# ESP32S3_RADIO register map
File version: 0.1.0
Registers are 32-bit, read-write, no defined reset value unless marked. A register's access mark holds for its fields unless they carry their own. Offsets are from the block's base; [hi:lo] are bit positions; {n}, {i} and the like mark numbered series.

## DUMP — Dump and DAC engine The Wi-Fi MAC's debug dump engine moves raw baseband words between the radio and one 64 KiB SRAM bank (see "SRAM bank ownership"). Its page, 0x60033000, has no name in the HAL. Layout from upstream esp-sdr; the DAC side from librftest's `dactrig()`. **Wi-Fi MAC interrupt.** CPU interrupt line 0 (`ETS_WMAC_INUM`, `modules/hal/espressif/components/soc/esp32s3/include/soc/soc.h:212`); `esp_sdr_ring_run()` disables it on its CPU (hardware-quirks.md, "Capture and DAC engine"; `lib/esp_sdr/src/esp_sdr_ring.c:508-538`).
Base 0x60033000
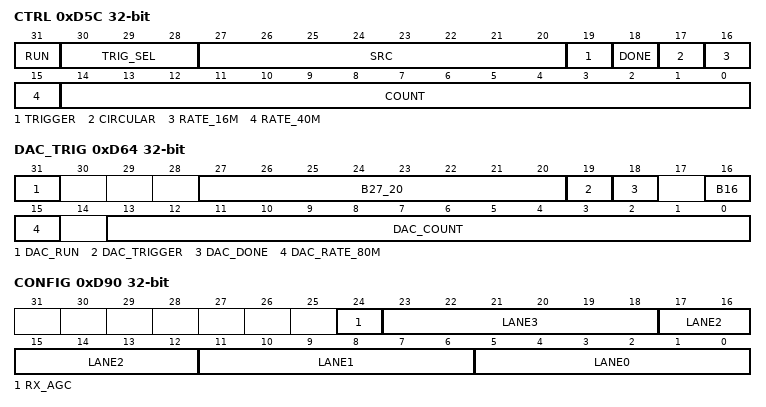
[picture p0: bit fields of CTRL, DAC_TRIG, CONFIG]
0xD5C CTRL — Receive side: run, trigger and count of a capture With neither DUMP_RATE_16M nor DUMP_RATE_40M the engine captures at 80 MS/s (4096 samples in 51 to 60 us). One-shot sequence: DUMP_CTRL_REG = 0, DUMP_CONFIG_REG, bank select, `DUMP_RUN | rate | count`, the same with DUMP_TRIGGER, the same without, poll DUMP_DONE, DUMP_CTRL_REG = 0, restore the bank select. The engine can stop early without any error flag (hardware-quirks.md, "Capture and DAC engine"). Evidence: `lib/esp_sdr/src/esp_sdr_rx.c:246-326` (sequence), `lib/esp_sdr/src/esp_sdr_rx.c:287-293, 321-323` (early stop)
  [31] RUN — Enables the engine. Evidence: *working* `lib/esp_sdr/src/esp_sdr_rx.c:300-310`
  [30:28] TRIG_SEL — The vendor `adctrig()`'s second argument: 0 = software trigger (DUMP_TRIGGER); 5 and 6 make it send frames while it waits. Seen 0. The trigger select could take work off the CPU; lead, not tried. Evidence: *decompile* S3 `mac_common.o` Evidence: *decompile* S3 `libphy.a` (lead)
  [27:20] SRC — The vendor's third argument; upstream calls it the source. Seen 0. Evidence: *decompile* S3 `mac_common.o`; *upstream* `modules/lib/esp-sdr/main/targets/esp32s3/receiver.c:164`
  [19] TRIGGER wo — Write 1, then 0, to start a one-shot capture. Evidence: *working* `lib/esp_sdr/src/esp_sdr_rx.c:308-310`
  [18] DONE ro — Reads 1 once DUMP_COUNT words are written; the library gives up after 20 ms. Evidence: *working* `lib/esp_sdr/src/esp_sdr_rx.c:311-314`
  [17] CIRCULAR — With DUMP_RUN and no trigger, the engine writes continuously round a 16384-pair ring (0x00024000 = this bit plus count 16384). In `adctrig()` the same bit skips the final count check. Evidence: *working* `lib/esp_sdr/src/esp_sdr_priv.h:290-294`, `lib/esp_sdr/src/esp_sdr_ring.c:1287`; *decompile* S3 `mac_common.o`
  [16] RATE_16M — Separate 16 MS/s path: 4096 samples in 256 us. `adctrig()` sets it unless bit 0 of its fourth argument is set. Evidence: *measured* `apps/capture/README.rst:56`; *upstream* (USRP B210) `modules/lib/esp-sdr/main/targets/esp32s3/receiver.c:161-163`; *decompile* S3 `mac_common.o`
  [15] RATE_40M — 80 MS/s halved, through the radio's decimation filter (each symbol spread over about +-8 samples, same MER as 80 MS/s): 4096 samples in 102 us. Evidence: *measured* `apps/capture/README.rst:53`, hardware-quirks.md, "Receiving at 40 MS/s"
  [14:0] COUNT — Words to capture, 256 to 16380. The library uses bits 13:0 (at most 16380, `ESP_SDR_SAMPLES_MAX`); `adctrig()` writes count + 1 and checks a 15-bit written count, and the ring writes 16384 (bit 14), so the field is probably 15 bits wide. Evidence: *working* `lib/esp_sdr/src/esp_sdr_priv.h:34`; *decompile* S3 `mac_common.o`
0xD60 WRITE_INDEX — Words written by a capture; the live write index in circular mode No read pointer is known for the DAC side; loop playback runs open loop on CCOUNT. Evidence: *measured* `lib/esp_sdr/src/esp_sdr_priv.h:237-245` (no DAC read pointer)
  [14:0] WRITE_INDEX ro — Words written, a 15-bit value: after DUMP_DONE, `adctrig()` compares it with count + 1. In circular mode bits 13:0 are the live write index, mod 16384, advancing whichever bank is selected; the ring times its bank switches on it. Evidence: *decompile* S3 `mac_common.o` (words written) Evidence: *working* `lib/esp_sdr/src/esp_sdr_ring.c:43, 139-142`; *upstream* `modules/lib/esp-sdr/main/common/ring_capture.c:112` (circular mode)
0xD64 DAC_TRIG — Transmit side: run, trigger and count of a playback 8 bytes above DUMP_CTRL_REG. - Writing 0 stops the engine at once (`esp_sdr_dac_halt()`). - In loop mode the DAC clock is exact (CPU stores to other banks do not slow it) and the engine reads whichever bank is selected at the moment, so a bank switch takes effect mid-pass. - The vendor's `dactrig(count, a2, a3, ...)` fills bank 2 (0x3fcd0000) with a ramp, writes count to DUMP_DAC_COUNT and bits 27:20, sets DUMP_DAC_RATE_80M unless a2 is 1, sets DUMP_DAC_TRIGGER (and leaves it set) only if a3 is not 0, sets DUMP_DAC_RUN, polls its own DUMP_DAC_DONE, waits 10 ms and clears DUMP_CTRL_REG (0x60033d5c), not itself. It never writes the bank select. The library skips the ramp so the caller's samples survive, and clears DUMP_CTRL_REG after every transmit session as well. - The front end must be forced to transmit, or only a spur near -6 MHz leaks (FE_FORCE_TXON, see "Front end"). Evidence: *measured* `lib/esp_sdr/src/esp_sdr_priv.h:237-245` (loop mode) Evidence: *decompile* S3 `mac_common.o` (`dactrig()`) Evidence: `lib/esp_sdr/src/esp_sdr_tx.c:272-273` (the library skips the ramp, clears DUMP_CTRL_REG)
  [31] DAC_RUN — Run bit; `dactrig()` sets it. Evidence: *working* `lib/esp_sdr/src/esp_sdr_tx.c:158-166`
  [27:20] B27_20 — `dactrig()` writes count & 0xff here; no effect on the rate. Evidence: *measured* `lib/esp_sdr/src/esp_sdr_priv.h:47-49`; *decompile* S3 `mac_common.o`
  [19] DAC_TRIGGER — Pulsed: one pass. Held: the engine replays the first DUMP_DAC_COUNT words back to back, gapless, until the register is cleared. A retrigger leaves a hole of about 1.35 us. Evidence: *measured* `lib/esp_sdr/src/esp_sdr_tx.c:163-166, 253-263`, `lib/esp_sdr/src/esp_sdr_priv.h:237-245`
  [18] DAC_DONE ro — Done flag; `dactrig()` polls it. Evidence: *working* `lib/esp_sdr/src/esp_sdr_tx.c:167-169`
  [16] B16 — No effect on the rate: there is no 16 MS/s DAC rate. Evidence: *measured* `lib/esp_sdr/src/esp_sdr_priv.h:47-49`
  [15] DAC_RATE_80M — The DAC has its own clock: 1 = 80 MS/s, 0 = 40 MS/s. 40 MS/s gives about 4 dB less MER. Evidence: *measured* `lib/esp_sdr/src/esp_sdr_priv.h:47-50`, hardware-quirks.md
  [13:0] DAC_COUNT — Words to play, 256 to 16380. Evidence: *working* `lib/esp_sdr/src/esp_sdr_tx.c:158-159`
0xD90 CONFIG — Lane selectors: the sources packed into a dump word Four 6-bit lane selectors (lane n in bits 6n+5:6n) choose the internal sources packed into a dump word; 0x000c2040 selects sources 0, 1, 2, 3: receive I/Q. librftest's `mac_init()` writes 0x000c2040 here once; the library writes it before every capture and ring run. The reading as lane selectors is upstream's. Only sources 0 to 3 are ever used. The others could take work off the CPU; lead, not tried. Evidence: *working* `lib/esp_sdr/src/esp_sdr_priv.h:35-37`; *upstream* `modules/lib/esp-sdr/main/targets/esp32s3/receiver.c:159` (lane selectors) Evidence: *decompile* S3 `mac_common.o` (`mac_init()`) Evidence: *decompile* S3 `libphy.a` (lead)
  [24] RX_AGC — Upstream probe flag (`rx_agc`). Seen 0. Evidence: *upstream* `modules/lib/esp-sdr/main/targets/esp32s3/receiver.c:159`
  [6n+5:6n] LANE{n} (n=0..3) — Source of lane {n}; {n} for receive I/Q.

## Notices in the file
SPDX-License-Identifier: GPL-3.0-or-later
